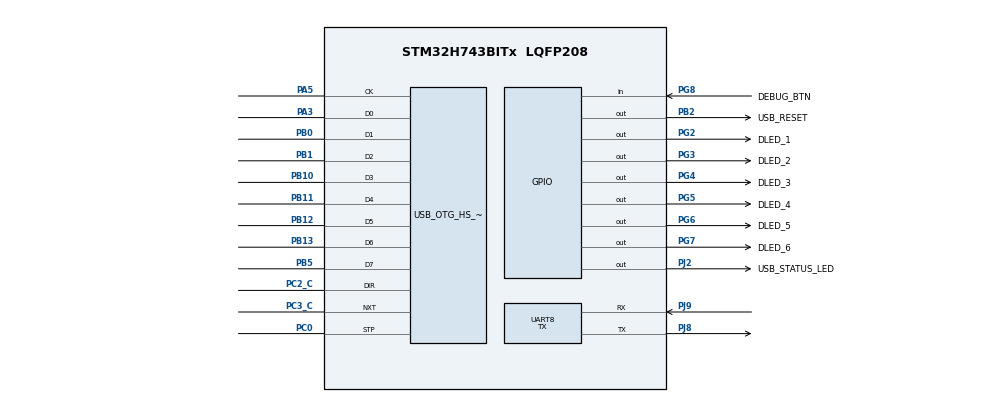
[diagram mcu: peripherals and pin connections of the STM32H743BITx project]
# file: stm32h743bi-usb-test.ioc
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CORTEX_M7.CPU_DCache=Enabled
CORTEX_M7.CPU_ICache=Enabled
Mcu.Family=STM32H7
Mcu.Name=STM32H743BITx
Mcu.Package=LQFP208
NVIC.OTG_HS_IRQn=true\:0\:0\:false\:false\:true\:false\:true
NVIC.PriorityGroup=NVIC_PRIORITYGROUP_4
PA13\ (JTMS/SWDIO).Mode=Trace_Asynchronous_SW
PA13\ (JTMS/SWDIO).Signal=DEBUG_JTMS-SWDIO
PA14\ (JTCK/SWCLK).Mode=Trace_Asynchronous_SW
PA14\ (JTCK/SWCLK).Signal=DEBUG_JTCK-SWCLK
PA15\ (JTDI).Signal=DEBUG_JTDI
PA3.Mode=Device_HS
PA3.Signal=USB_OTG_HS_ULPI_D0
PA5.Mode=Device_HS
PA5.Signal=USB_OTG_HS_ULPI_CK
PB0.Mode=Device_HS
PB0.Signal=USB_OTG_HS_ULPI_D1
PB1.Mode=Device_HS
PB1.Signal=USB_OTG_HS_ULPI_D2
PB10.Mode=Device_HS
PB10.Signal=USB_OTG_HS_ULPI_D3
PB11.Mode=Device_HS
PB11.Signal=USB_OTG_HS_ULPI_D4
PB12.Mode=Device_HS
PB12.Signal=USB_OTG_HS_ULPI_D5
PB13.Mode=Device_HS
PB13.Signal=USB_OTG_HS_ULPI_D6
PB2.GPIO_Label=USB_RESET
PB2.Signal=GPIO_Output
PB3\ (JTDO/TRACESWO).Mode=Trace_Asynchronous_SW
PB3\ (JTDO/TRACESWO).Signal=DEBUG_JTDO-SWO
PB5.Mode=Device_HS
PB5.Signal=USB_OTG_HS_ULPI_D7
PC0.Mode=Device_HS
PC0.Signal=USB_OTG_HS_ULPI_STP
PC14-OSC32_IN\ (OSC32_IN).Mode=LSE-External-Clock-Source
PC14-OSC32_IN\ (OSC32_IN).Signal=RCC_OSC32_IN
PC2_C.Mode=Device_HS
PC2_C.Signal=USB_OTG_HS_ULPI_DIR
PC3_C.Mode=Device_HS
PC3_C.Signal=USB_OTG_HS_ULPI_NXT
PG2.GPIO_Label=DLED_1
PG2.Signal=GPIO_Output
PG3.GPIO_Label=DLED_2
PG3.Signal=GPIO_Output
PG4.GPIO_Label=DLED_3
PG4.Signal=GPIO_Output
PG5.GPIO_Label=DLED_4
PG5.Signal=GPIO_Output
PG6.GPIO_Label=DLED_5
PG6.Signal=GPIO_Output
PG7.GPIO_Label=DLED_6
PG7.Signal=GPIO_Output
PG8.GPIO_Label=DEBUG_BTN
PG8.Signal=GPIO_Input
PH0-OSC_IN\ (PH0).Mode=HSE-External-Clock-Source
PH0-OSC_IN\ (PH0).Signal=RCC_OSC_IN
PJ2.GPIO_Label=USB_STATUS_LED
PJ2.Signal=GPIO_Output
PJ8.Mode=Asynchronous
PJ8.Signal=UART8_TX
PJ9.Mode=Asynchronous
PJ9.Signal=UART8_RX
ProjectManager.HeapSize=0x200
ProjectManager.StackSize=0x400
ProjectManager.TargetToolchain=STM32CubeIDE
RCC.ADCFreq_Value=48000000
RCC.APB1Freq_Value=120000000
RCC.APB2Freq_Value=120000000
RCC.APB3Freq_Value=120000000
RCC.APB4Freq_Value=120000000
RCC.CortexFreq_Value=480000000
RCC.D1PPRE=RCC_APB3_DIV2
RCC.D2PPRE1=RCC_APB1_DIV2
RCC.D2PPRE2=RCC_APB2_DIV2
RCC.D3PPRE=RCC_APB4_DIV2
RCC.DIVM1=12
RCC.DIVM3=6
RCC.DIVN1=480
RCC.DIVN2=128
RCC.DIVN3=48
RCC.DIVQ3=4
RCC.EnbaleCSS=true
RCC.HCLKFreq_Value=240000000
RCC.HPRE=RCC_HCLK_DIV2
RCC.HSE_VALUE=24000000
RCC.PLLSourceVirtual=RCC_PLLSOURCE_HSE
RCC.SYSCLKFreq_VALUE=480000000
RCC.SYSCLKSource=RCC_SYSCLKSOURCE_PLLCLK
RCC.USBCLockSelection=RCC_USBCLKSOURCE_PLL3
RCC.USBFreq_Value=48000000
UART8.Mode=MODE_TX
USB_DEVICE.CLASS_NAME_HS=CDC
USB_DEVICE.USBD_DEBUG_LEVEL-CDC_HS=3
USB_DEVICE.VirtualMode-CDC_HS=Cdc
USB_DEVICE.VirtualModeHS=Cdc_HS
USB_OTG_HS.VirtualMode-Device_HS=Device_HS
VP_USB_DEVICE_VS_USB_DEVICE_CDC_HS.Mode=CDC_HS
board=custom

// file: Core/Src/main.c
/* USER CODE BEGIN Header */
/**
  ******************************************************************************
  * @file           : main.c
  * @brief          : Main program body
  ******************************************************************************
  * @attention
  *
  * <h2><center>&copy; Copyright (c) 2021 STMicroelectronics.
  * All rights reserved.</center></h2>
  *
  * This software component is licensed by ST under Ultimate Liberty license
  * SLA0044, the "License"; You may not use this file except in compliance with
  * the License. You may obtain a copy of the License at:
  *                             www.st.com/SLA0044
  *
  ******************************************************************************
  */
/* USER CODE END Header */
#include "main.h"
#include "usb_device.h"
#include "retarget.h"

UART_HandleTypeDef huart8;

void SystemClock_Config(void);
static void MX_GPIO_Init(void);
static void MX_UART8_Init(void);

int main(void)
{

  /* Enable I-Cache---------------------------------------------------------*/
  SCB_EnableICache();

  /* Enable D-Cache---------------------------------------------------------*/
  SCB_EnableDCache();

  /* MCU Configuration--------------------------------------------------------*/

  /* Reset of all peripherals, Initializes the Flash interface and the Systick. */
  HAL_Init();

  /* Configure the system clock */
  SystemClock_Config();

  /* Initialize all configured peripherals */
  MX_GPIO_Init();
  MX_UART8_Init();
  /* USER CODE BEGIN 2 */
  RetargetInit(&huart8);
  printf("\n\n\nInitializing USB Device\r\n");
  MX_USB_DEVICE_Init();
  printf("USB Device Initialized\r\n");
  /* USER CODE END 2 */

  /* Infinite loop */
  /* USER CODE BEGIN WHILE */
  printf("Starting Idle Loop\r\n");
  while (1)
  {
    /* USER CODE END WHILE */

  }
}

void SystemClock_Config(void)
{
  RCC_OscInitTypeDef RCC_OscInitStruct = {0};
  RCC_ClkInitTypeDef RCC_ClkInitStruct = {0};
  RCC_PeriphCLKInitTypeDef PeriphClkInitStruct = {0};

  /** Supply configuration update enable
  */
  HAL_PWREx_ConfigSupply(PWR_LDO_SUPPLY);
  /** Configure the main internal regulator output voltage
  */
  __HAL_PWR_VOLTAGESCALING_CONFIG(PWR_REGULATOR_VOLTAGE_SCALE0);

  while(!__HAL_PWR_GET_FLAG(PWR_FLAG_VOSRDY)) {}
  /** Initializes the RCC Oscillators according to the specified parameters
  * in the RCC_OscInitTypeDef structure.
  */
  RCC_OscInitStruct.OscillatorType = RCC_OSCILLATORTYPE_HSE;
  RCC_OscInitStruct.HSEState = RCC_HSE_BYPASS;
  RCC_OscInitStruct.PLL.PLLState = RCC_PLL_ON;
  RCC_OscInitStruct.PLL.PLLSource = RCC_PLLSOURCE_HSE;
  RCC_OscInitStruct.PLL.PLLM = 12;
  RCC_OscInitStruct.PLL.PLLN = 480;
  RCC_OscInitStruct.PLL.PLLP = 2;
  RCC_OscInitStruct.PLL.PLLQ = 2;
  RCC_OscInitStruct.PLL.PLLR = 2;
  RCC_OscInitStruct.PLL.PLLRGE = RCC_PLL1VCIRANGE_1;
  RCC_OscInitStruct.PLL.PLLVCOSEL = RCC_PLL1VCOWIDE;
  RCC_OscInitStruct.PLL.PLLFRACN = 0;
  if (HAL_RCC_OscConfig(&RCC_OscInitStruct) != HAL_OK)
  {
    Error_Handler();
  }
  /** Initializes the CPU, AHB and APB buses clocks
  */
  RCC_ClkInitStruct.ClockType = RCC_CLOCKTYPE_HCLK|RCC_CLOCKTYPE_SYSCLK
                              |RCC_CLOCKTYPE_PCLK1|RCC_CLOCKTYPE_PCLK2
                              |RCC_CLOCKTYPE_D3PCLK1|RCC_CLOCKTYPE_D1PCLK1;
  RCC_ClkInitStruct.SYSCLKSource = RCC_SYSCLKSOURCE_PLLCLK;
  RCC_ClkInitStruct.SYSCLKDivider = RCC_SYSCLK_DIV1;
  RCC_ClkInitStruct.AHBCLKDivider = RCC_HCLK_DIV2;
  RCC_ClkInitStruct.APB3CLKDivider = RCC_APB3_DIV2;
  RCC_ClkInitStruct.APB1CLKDivider = RCC_APB1_DIV2;
  RCC_ClkInitStruct.APB2CLKDivider = RCC_APB2_DIV2;
  RCC_ClkInitStruct.APB4CLKDivider = RCC_APB4_DIV2;

  if (HAL_RCC_ClockConfig(&RCC_ClkInitStruct, FLASH_LATENCY_4) != HAL_OK)
  {
    Error_Handler();
  }
  PeriphClkInitStruct.PeriphClockSelection = RCC_PERIPHCLK_UART8;
  PeriphClkInitStruct.Usart234578ClockSelection = RCC_USART234578CLKSOURCE_D2PCLK1;
  if (HAL_RCCEx_PeriphCLKConfig(&PeriphClkInitStruct) != HAL_OK)
  {
    Error_Handler();
  }
  /** Enables the Clock Security System
  */
  HAL_RCC_EnableCSS();
}

static void MX_UART8_Init(void)
{

  huart8.Instance = UART8;
  huart8.Init.BaudRate = 115200;
  huart8.Init.WordLength = UART_WORDLENGTH_8B;
  huart8.Init.StopBits = UART_STOPBITS_1;
  huart8.Init.Parity = UART_PARITY_NONE;
  huart8.Init.Mode = UART_MODE_TX;
  huart8.Init.HwFlowCtl = UART_HWCONTROL_NONE;
  huart8.Init.OverSampling = UART_OVERSAMPLING_16;
  huart8.Init.OneBitSampling = UART_ONE_BIT_SAMPLE_DISABLE;
  huart8.Init.ClockPrescaler = UART_PRESCALER_DIV1;
  huart8.AdvancedInit.AdvFeatureInit = UART_ADVFEATURE_NO_INIT;
  if (HAL_UART_Init(&huart8) != HAL_OK)
  {
    Error_Handler();
  }
  if (HAL_UARTEx_SetTxFifoThreshold(&huart8, UART_TXFIFO_THRESHOLD_1_8) != HAL_OK)
  {
    Error_Handler();
  }
  if (HAL_UARTEx_SetRxFifoThreshold(&huart8, UART_RXFIFO_THRESHOLD_1_8) != HAL_OK)
  {
    Error_Handler();
  }
  if (HAL_UARTEx_DisableFifoMode(&huart8) != HAL_OK)
  {
    Error_Handler();
  }

}

static void MX_GPIO_Init(void)
{
  GPIO_InitTypeDef GPIO_InitStruct = {0};

  /* GPIO Ports Clock Enable */
  __HAL_RCC_GPIOC_CLK_ENABLE();
  __HAL_RCC_GPIOH_CLK_ENABLE();
  __HAL_RCC_GPIOA_CLK_ENABLE();
  __HAL_RCC_GPIOB_CLK_ENABLE();
  __HAL_RCC_GPIOJ_CLK_ENABLE();
  __HAL_RCC_GPIOG_CLK_ENABLE();

  /*Configure GPIO pin Output Level */
  HAL_GPIO_WritePin(USB_RESET_GPIO_Port, USB_RESET_Pin, GPIO_PIN_RESET);

  /*Configure GPIO pin Output Level */
  HAL_GPIO_WritePin(USB_STATUS_LED_GPIO_Port, USB_STATUS_LED_Pin, GPIO_PIN_RESET);

  /*Configure GPIO pin Output Level */
  HAL_GPIO_WritePin(GPIOG, DLED_1_Pin|DLED_2_Pin|DLED_3_Pin|DLED_4_Pin
                          |DLED_5_Pin|DLED_6_Pin, GPIO_PIN_RESET);

  /*Configure GPIO pin : USB_RESET_Pin */
  GPIO_InitStruct.Pin = USB_RESET_Pin;
  GPIO_InitStruct.Mode = GPIO_MODE_OUTPUT_PP;
  GPIO_InitStruct.Pull = GPIO_NOPULL;
  GPIO_InitStruct.Speed = GPIO_SPEED_FREQ_LOW;
  HAL_GPIO_Init(USB_RESET_GPIO_Port, &GPIO_InitStruct);

  /*Configure GPIO pin : USB_STATUS_LED_Pin */
  GPIO_InitStruct.Pin = USB_STATUS_LED_Pin;
  GPIO_InitStruct.Mode = GPIO_MODE_OUTPUT_PP;
  GPIO_InitStruct.Pull = GPIO_NOPULL;
  GPIO_InitStruct.Speed = GPIO_SPEED_FREQ_LOW;
  HAL_GPIO_Init(USB_STATUS_LED_GPIO_Port, &GPIO_InitStruct);

  /*Configure GPIO pins : DLED_1_Pin DLED_2_Pin DLED_3_Pin DLED_4_Pin
                           DLED_5_Pin DLED_6_Pin */
  GPIO_InitStruct.Pin = DLED_1_Pin|DLED_2_Pin|DLED_3_Pin|DLED_4_Pin
                          |DLED_5_Pin|DLED_6_Pin;
  GPIO_InitStruct.Mode = GPIO_MODE_OUTPUT_PP;
  GPIO_InitStruct.Pull = GPIO_NOPULL;
  GPIO_InitStruct.Speed = GPIO_SPEED_FREQ_LOW;
  HAL_GPIO_Init(GPIOG, &GPIO_InitStruct);

  /*Configure GPIO pin : DEBUG_BTN_Pin */
  GPIO_InitStruct.Pin = DEBUG_BTN_Pin;
  GPIO_InitStruct.Mode = GPIO_MODE_INPUT;
  GPIO_InitStruct.Pull = GPIO_NOPULL;
  HAL_GPIO_Init(DEBUG_BTN_GPIO_Port, &GPIO_InitStruct);

}

void Error_Handler(void)
{
  /* USER CODE BEGIN Error_Handler_Debug */
  /* User can add his own implementation to report the HAL error return state */
	printf("Error_Handler\r\n");
  __disable_irq();
  while (1)
  {
  }
  /* USER CODE END Error_Handler_Debug */
}

#ifdef  USE_FULL_ASSERT
/**
  * @brief  Reports the name of the source file and the source line number
  *         where the assert_param error has occurred.
  * @param  file: pointer to the source file name
  * @param  line: assert_param error line source number
  * @retval None
  */
void assert_failed(uint8_t *file, uint32_t line)
{
  /* USER CODE BEGIN 6 */
	printf("Assert Failed: file %s line %lu\r\n", file, line);
  /* User can add his own implementation to report the file name and line number,
     ex: printf("Wrong parameters value: file %s on line %d\r\n", file, line) */
  /* USER CODE END 6 */
}
#endif /* USE_FULL_ASSERT */

/************************ (C) COPYRIGHT STMicroelectronics *****END OF FILE****/
